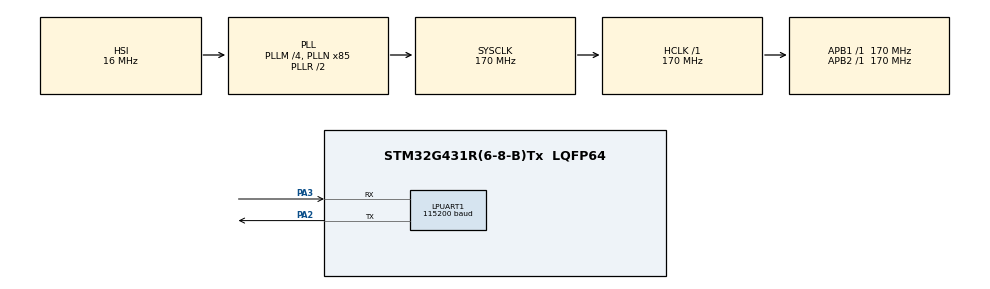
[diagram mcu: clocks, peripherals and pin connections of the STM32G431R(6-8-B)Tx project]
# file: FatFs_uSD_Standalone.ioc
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FATFS.BOARD_NAME=stm32g431rb
FATFS.DISKIO_CODE=1
FATFS._CODE_PAGE=850
FATFS._FS_EXFAT=0
FATFS._FS_LOCK=2
FATFS._FS_MINIMIZE=0
FATFS._FS_NOFSINFO=0
FATFS._FS_NORTC=0
FATFS._FS_READONLY=0
FATFS._FS_REENTRANT=0
FATFS._FS_RPATH=0
FATFS._FS_TIMEOUT=1000
FATFS._FS_TINY=0
FATFS._LFN_UNICODE=0
FATFS._MAX_LFN=255
FATFS._MAX_SS=512
FATFS._MIN_SS=512
FATFS._MULTI_PARTITION=0
FATFS._STRF_ENCODE=3
FATFS._USE_CHMOD=0
FATFS._USE_EXPAND=0
FATFS._USE_FASTSEEK=1
FATFS._USE_FIND=0
FATFS._USE_FORWARD=0
FATFS._USE_LABEL=0
FATFS._USE_LFN=0
FATFS._USE_MKFS=1
FATFS._USE_STRFUNC=0
FATFS._USE_TRIM=0
FATFS._VOLUMES=1
LPUART1.BaudRate=115200
LPUART1.Parity=UART_PARITY_ODD
LPUART1.WordLength=UART_WORDLENGTH_8B
Mcu.Family=STM32G4
Mcu.Name=STM32G431R(6-8-B)Tx
Mcu.Package=LQFP64
NVIC.PriorityGroup=NVIC_PRIORITYGROUP_4
PA2.Mode=Asynchronous
PA2.Signal=LPUART1_TX
PA3.Mode=Asynchronous
PA3.Signal=LPUART1_RX
ProjectManager.HeapSize=0x800
ProjectManager.StackSize=0x1200
ProjectManager.TargetToolchain=EWARM V8.32
RCC.ADC12Freq_Value=170000000
RCC.AHBFreq_Value=170000000
RCC.APB1Freq_Value=170000000
RCC.APB1TimFreq_Value=170000000
RCC.APB2Freq_Value=170000000
RCC.APB2TimFreq_Value=170000000
RCC.CortexFreq_Value=170000000
RCC.EXTERNAL_CLOCK_VALUE=12288000
RCC.HCLKFreq_Value=170000000
RCC.HSE_VALUE=24000000
RCC.HSI48_VALUE=48000000
RCC.HSI_VALUE=16000000
RCC.LSE_VALUE=32768
RCC.PLLM=RCC_PLLM_DIV4
RCC.PLLN=85
RCC.SYSCLKFreq_VALUE=170000000
RCC.SYSCLKSource=RCC_SYSCLKSOURCE_PLLCLK
RCC.USBFreq_Value=170000000
RCC.VCOOutputFreq_Value=340000000
VP_FATFS_VS_Generic.Mode=User_defined
VP_SYS_VS_DBSignals.Mode=DisableDeadBatterySignals
board=custom

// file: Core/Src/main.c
/* USER CODE BEGIN Header */
/**
  ******************************************************************************
  * @file    FatFs/FatFs_uSD_Standalone/Core/Src/main.c
  * @author  MCD Application Team
  * @brief   Main program body
  *          This sample code shows how to use FatFs with uSD card drive.
  ******************************************************************************
  * @attention
  *
  * <h2><center>&copy; Copyright (c) 2019 STMicroelectronics.
  * All rights reserved.</center></h2>
  *
  * This software component is licensed by ST under BSD 3-Clause license,
  * the "License"; You may not use this file except in compliance with the
  * License. You may obtain a copy of the License at:
  *                        opensource.org/licenses/BSD-3-Clause
  *
  ******************************************************************************
  */
/* USER CODE END Header */

#include "main.h"
#include "app_fatfs.h"

/* USER CODE BEGIN PM */
#ifdef __GNUC__
/* With GCC, small printf (option LD Linker->Libraries->Small printf
   set to 'Yes') calls __io_putchar() */
#define PUTCHAR_PROTOTYPE int __io_putchar(int ch)
#else
#define PUTCHAR_PROTOTYPE int fputc(int ch, FILE *f)
#endif /* __GNUC__ */
/* USER CODE END PM */

UART_HandleTypeDef hlpuart1;

/* USER CODE BEGIN PV */
int32_t ProcessStatus = 0;
/* USER CODE END PV */

void SystemClock_Config(void);
static void MX_GPIO_Init(void);
static void MX_LPUART1_UART_Init(void);
/* USER CODE BEGIN PFP */
void Success_Handler(void);
/* USER CODE END PFP */

int main(void)
{

  /* MCU Configuration--------------------------------------------------------*/

  /* Reset of all peripherals, Initializes the Flash interface and the Systick. */
  HAL_Init();

  /* Configure the system clock */
  SystemClock_Config();

  /* USER CODE BEGIN SysInit */

  /* Initialize the micro SD Card */
  ADAFRUIT_802_SD_Init(0);
  /* USER CODE END SysInit */

  /* Initialize all configured peripherals */
  MX_GPIO_Init();
  MX_LPUART1_UART_Init();
  MX_FATFS_Init();

  /* Infinite loop */
  /* USER CODE BEGIN WHILE */
  while (1)
  {
    ProcessStatus = MX_FATFS_Process();
    /* Call middleware background task */
    if (ProcessStatus == APP_ERROR)
    {
      Error_Handler();
    }
    else if (ProcessStatus == APP_OK)
    {
      Success_Handler();
    }

    /* USER CODE END WHILE */

  }
}

void SystemClock_Config(void)
{
  RCC_OscInitTypeDef RCC_OscInitStruct = {0};
  RCC_ClkInitTypeDef RCC_ClkInitStruct = {0};
  RCC_PeriphCLKInitTypeDef PeriphClkInit = {0};

  /** Configure the main internal regulator output voltage
  */
  HAL_PWREx_ControlVoltageScaling(PWR_REGULATOR_VOLTAGE_SCALE1_BOOST);
  /** Initializes the CPU, AHB and APB busses clocks
  */
  RCC_OscInitStruct.OscillatorType = RCC_OSCILLATORTYPE_HSI;
  RCC_OscInitStruct.HSIState = RCC_HSI_ON;
  RCC_OscInitStruct.HSICalibrationValue = 64;
  RCC_OscInitStruct.PLL.PLLState = RCC_PLL_ON;
  RCC_OscInitStruct.PLL.PLLSource = RCC_PLLSOURCE_HSI;
  RCC_OscInitStruct.PLL.PLLM = RCC_PLLM_DIV4;
  RCC_OscInitStruct.PLL.PLLN = 85;
  RCC_OscInitStruct.PLL.PLLP = RCC_PLLP_DIV2;
  RCC_OscInitStruct.PLL.PLLQ = RCC_PLLQ_DIV2;
  RCC_OscInitStruct.PLL.PLLR = RCC_PLLR_DIV2;
  if (HAL_RCC_OscConfig(&RCC_OscInitStruct) != HAL_OK)
  {
    Error_Handler();
  }
  /** Initializes the CPU, AHB and APB busses clocks
  */
  RCC_ClkInitStruct.ClockType = RCC_CLOCKTYPE_HCLK|RCC_CLOCKTYPE_SYSCLK
                              |RCC_CLOCKTYPE_PCLK1|RCC_CLOCKTYPE_PCLK2;
  RCC_ClkInitStruct.SYSCLKSource = RCC_SYSCLKSOURCE_PLLCLK;
  RCC_ClkInitStruct.AHBCLKDivider = RCC_SYSCLK_DIV1;
  RCC_ClkInitStruct.APB1CLKDivider = RCC_HCLK_DIV1;
  RCC_ClkInitStruct.APB2CLKDivider = RCC_HCLK_DIV1;

  if (HAL_RCC_ClockConfig(&RCC_ClkInitStruct, FLASH_LATENCY_8) != HAL_OK)
  {
    Error_Handler();
  }
  /** Initializes the peripherals clocks
  */
  PeriphClkInit.PeriphClockSelection = RCC_PERIPHCLK_LPUART1;
  PeriphClkInit.Lpuart1ClockSelection = RCC_LPUART1CLKSOURCE_PCLK1;
  if (HAL_RCCEx_PeriphCLKConfig(&PeriphClkInit) != HAL_OK)
  {
    Error_Handler();
  }
}

static void MX_LPUART1_UART_Init(void)
{

  hlpuart1.Instance = LPUART1;
  hlpuart1.Init.BaudRate = 115200;
  hlpuart1.Init.WordLength = UART_WORDLENGTH_8B;
  hlpuart1.Init.StopBits = UART_STOPBITS_1;
  hlpuart1.Init.Parity = UART_PARITY_ODD;
  hlpuart1.Init.Mode = UART_MODE_TX_RX;
  hlpuart1.Init.HwFlowCtl = UART_HWCONTROL_NONE;
  hlpuart1.Init.OneBitSampling = UART_ONE_BIT_SAMPLE_DISABLE;
  hlpuart1.AdvancedInit.AdvFeatureInit = UART_ADVFEATURE_NO_INIT;
  if (HAL_UART_Init(&hlpuart1) != HAL_OK)
  {
    Error_Handler();
  }
  if (HAL_UARTEx_SetTxFifoThreshold(&hlpuart1, UART_TXFIFO_THRESHOLD_1_8) != HAL_OK)
  {
    Error_Handler();
  }
  if (HAL_UARTEx_SetRxFifoThreshold(&hlpuart1, UART_RXFIFO_THRESHOLD_1_8) != HAL_OK)
  {
    Error_Handler();
  }
  if (HAL_UARTEx_DisableFifoMode(&hlpuart1) != HAL_OK)
  {
    Error_Handler();
  }

}

static void MX_GPIO_Init(void)
{

  /* GPIO Ports Clock Enable */
  __HAL_RCC_GPIOA_CLK_ENABLE();

}

/* USER CODE BEGIN 4 */
/**
  * @brief  Retargets the C library printf function to the USART.
  * @param  None
  * @retval None
  */
PUTCHAR_PROTOTYPE
{
  /* Place your implementation of fputc here */
  /* e.g. write a character to the USART1 and Loop until the end of transmission */
  HAL_UART_Transmit(&hlpuart1, (uint8_t *)&ch, 1, 0xFFFF);

  return ch;
}

/**
  * @brief  This function is executed in case of success.
  * @retval None
  */
void Success_Handler(void)
{
  printf("** Success. ** \n\r");
  while(1)
  {
  }
}
/* USER CODE END 4 */

void Error_Handler(void)
{
  /* USER CODE BEGIN Error_Handler_Debug */
  /* User can add his own implementation to report the HAL error return state */
  printf("** Error. ** \n\r");
  while(1)
  {
  }
  /* USER CODE END Error_Handler_Debug */
}

/************************ (C) COPYRIGHT STMicroelectronics *****END OF FILE****/
